AUTOSAR XML (schema 4-2-2)
package /Acme/Constants
  constant specification CZero: value-spec=0
package /Acme/Interfaces
  client server interface ILocal
    operation Ping
package /Acme/Components
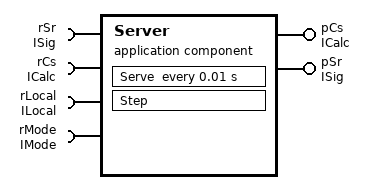
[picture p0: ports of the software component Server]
  application sw component type Server
    provide port pCs: provided-com-specs=[{operation=Add, queue-length=1}, {operation=Sub, queue-length=1}], provided-interface=ICalc
    provide port pSr: nonqueued-sender-com-spec=data-element=level, provided-interface=ISig
    4 x require port:
      rSr: required-interface=ISig
        required-com-specs:
          data-element=level, enable-update=true, init-value=constant-reference=CZero
          data-element=speed, handle-timeout-type=INVENTED
      rCs: required-interface=ICalc
      rLocal: required-interface=ILocal
      rMode: mode-switch-receiver-com-spec=enhanced-mode-api=false, required-interface=IMode
    behavior Behavior: handle-termination-and-restart=NO-SUPPORT
      timing event E_Tick: start-on-event=Serve, period=0.01
      operation invoked event E_Add: start-on-event=Serve, operation=pCs.Add
      operation invoked event E_Deep: start-on-event=Serve, operation=pCs.Add
      operation invoked event E_Backwards: start-on-event=Serve, operation=rCs.Add
      runnable Serve
      runnable Step
        data-receive-point-by-arguments:
          access R_rSr_level: accessed-variable=rSr.level
          access readWrongKind: accessed-variable=rCs.Add
        data-send-points:
          access sendLevel: accessed-variable=pSr.level
        sync call Call_rCs_Add: operation=rCs.Add, timeout=0
        sync call Call_rLocal_Ping: operation=rLocal.Ping, timeout=0
package /Acme/Compositions
  composition sw component type Top
    provide port pOut: provided-com-specs=[{data-element=level, handle-out-of-range=SATURATE}, torque], provided-interface=ISig
    component srv: type=Server
